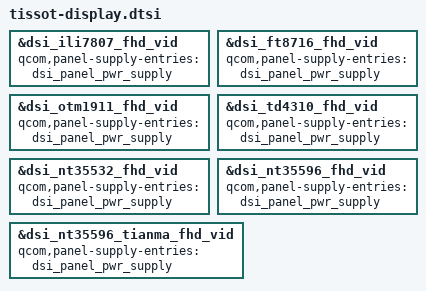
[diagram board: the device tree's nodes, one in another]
 /*
  * Copyright (c) 2015-2016, The Linux Foundation. All rights reserved.
  *
  * This program is free software; you can redistribute it and/or modify
  * it under the terms of the GNU General Public License version 2 and
  * only version 2 as published by the Free Software Foundation.
  *
  * This program is distributed in the hope that it will be useful,
  * but WITHOUT ANY WARRANTY; without even the implied warranty of
  * MERCHANTABILITY or FITNESS FOR A PARTICULAR PURPOSE.  See the
  * GNU General Public License for more details.
  */

&dsi_ili7807_fhd_vid {
	qcom,panel-supply-entries = <&dsi_panel_pwr_supply>;
};

&dsi_ft8716_fhd_vid {
	qcom,panel-supply-entries = <&dsi_panel_pwr_supply>;
};

&dsi_otm1911_fhd_vid {
	qcom,panel-supply-entries = <&dsi_panel_pwr_supply>;
};

&dsi_td4310_fhd_vid {
	qcom,panel-supply-entries = <&dsi_panel_pwr_supply>;
};

&dsi_nt35532_fhd_vid {
	qcom,panel-supply-entries = <&dsi_panel_pwr_supply>;
};

&dsi_nt35596_fhd_vid {
	qcom,panel-supply-entries = <&dsi_panel_pwr_supply>;
};

&dsi_nt35596_tianma_fhd_vid {
	qcom,panel-supply-entries = <&dsi_panel_pwr_supply>;
};
